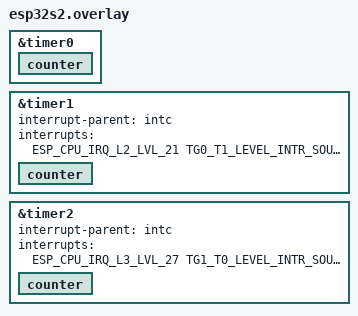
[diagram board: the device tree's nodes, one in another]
/*
 * Copyright (c) 2025-2026 Espressif Systems (Shanghai) Co., Ltd.
 *
 * SPDX-License-Identifier: Apache-2.0
 */

/*
 * The nested-ISR suite needs the three timers at three Xtensa interrupt
 * levels. timer0 keeps the shared level-1 line of the timer groups from the
 * SoC devicetree; timer1 and timer2 become dedicated consumers of intc on a
 * level-2 and a level-3 CPU line, which no other devicetree node uses.
 */

&timer0 {
	status = "okay";

	counter {
		status = "okay";
	};
};

&timer1 {
	interrupt-parent = <&intc>;
	interrupts = <ESP_CPU_IRQ_L2_LVL_21 TG0_T1_LEVEL_INTR_SOURCE 0>;
	status = "okay";

	counter {
		status = "okay";
	};
};

&timer2 {
	interrupt-parent = <&intc>;
	interrupts = <ESP_CPU_IRQ_L3_LVL_27 TG1_T0_LEVEL_INTR_SOURCE 0>;
	status = "okay";

	counter {
		status = "okay";
	};
};
